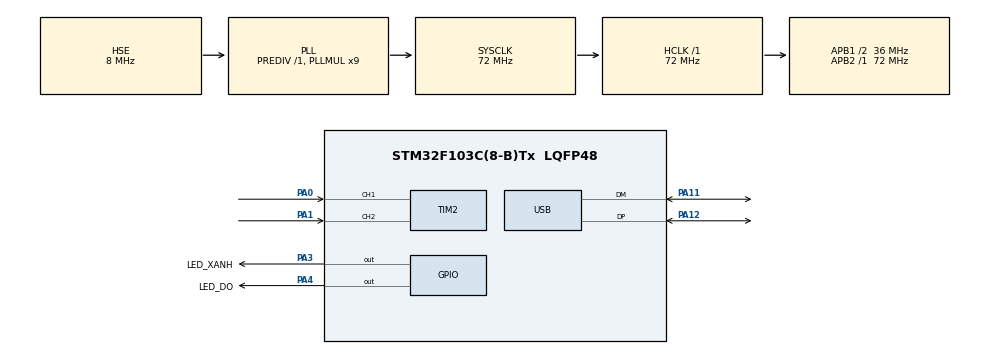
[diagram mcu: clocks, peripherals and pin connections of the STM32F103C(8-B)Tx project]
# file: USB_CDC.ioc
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Mcu.Family=STM32F1
Mcu.Name=STM32F103C(8-B)Tx
Mcu.Package=LQFP48
NVIC.PriorityGroup=NVIC_PRIORITYGROUP_4
NVIC.TIM3_IRQn=true\:0\:0\:false\:false\:true\:true\:true\:true
NVIC.USB_LP_CAN1_RX0_IRQn=true\:0\:0\:false\:false\:true\:false\:true\:true
PA0-WKUP.Signal=S_TIM2_CH1_ETR
PA1.Signal=S_TIM2_CH2
PA11.Mode=Device
PA11.Signal=USB_DM
PA12.Mode=Device
PA12.Signal=USB_DP
PA13.Mode=Serial_Wire
PA13.Signal=SYS_JTMS-SWDIO
PA14.Mode=Serial_Wire
PA14.Signal=SYS_JTCK-SWCLK
PA3.GPIO_Label=LED_XANH
PA3.GPIO_PuPd=GPIO_NOPULL
PA3.Signal=GPIO_Output
PA4.GPIO_Label=LED_DO
PA4.GPIO_PuPd=GPIO_NOPULL
PA4.Signal=GPIO_Output
PD0-OSC_IN.Mode=HSE-External-Oscillator
PD0-OSC_IN.Signal=RCC_OSC_IN
PD1-OSC_OUT.Mode=HSE-External-Oscillator
PD1-OSC_OUT.Signal=RCC_OSC_OUT
ProjectManager.HeapSize=0x200
ProjectManager.StackSize=0x400
ProjectManager.TargetToolchain=MDK-ARM V5
RCC.AHBFreq_Value=72000000
RCC.APB1CLKDivider=RCC_HCLK_DIV2
RCC.APB1Freq_Value=36000000
RCC.APB1TimFreq_Value=72000000
RCC.APB2Freq_Value=72000000
RCC.APB2TimFreq_Value=72000000
RCC.HCLKFreq_Value=72000000
RCC.PLLMUL=RCC_PLL_MUL9
RCC.PLLSourceVirtual=RCC_PLLSOURCE_HSE
RCC.SYSCLKFreq_VALUE=72000000
RCC.SYSCLKSource=RCC_SYSCLKSOURCE_PLLCLK
RCC.USBFreq_Value=48000000
RCC.USBPrescaler=RCC_USBCLKSOURCE_PLL_DIV1_5
SH.S_TIM2_CH1_ETR.0=TIM2_CH1,Encoder_Interface
SH.S_TIM2_CH2.0=TIM2_CH2,Encoder_Interface
TIM2.EncoderMode=TIM_ENCODERMODE_TI12
TIM3.Period=9999
TIM3.Prescaler=7199
USB_DEVICE.APP_RX_DATA_SIZE=128
USB_DEVICE.APP_TX_DATA_SIZE=128
USB_DEVICE.CLASS_NAME_FS=CDC
USB_DEVICE.VirtualMode=Cdc
USB_DEVICE.VirtualModeFS=Cdc_FS
VP_TIM3_VS_ClockSourceINT.Mode=Internal
VP_USB_DEVICE_VS_USB_DEVICE_CDC_FS.Mode=CDC_FS
board=custom

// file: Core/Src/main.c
/* USER CODE BEGIN Header */
/**
  ******************************************************************************
  * @file           : main.c
  * @brief          : Main program body
  ******************************************************************************
  * @attention
  *
  * Copyright (c) 2023 STMicroelectronics.
  * All rights reserved.
  *
  * This software is licensed under terms that can be found in the LICENSE file
  * in the root directory of this software component.
  * If no LICENSE file comes with this software, it is provided AS-IS.
  *
  ******************************************************************************
  */
/* USER CODE END Header */
#include "main.h"
#include "usb_device.h"

/* USER CODE BEGIN Includes */
#include "usbd_cdc_if.h"
#include "string.h"
#include "stdlib.h"
volatile short dem_xung = 0, pre_dem = 0;
uint16_t rate = 0;
uint8_t Rx_Buffer[128];
uint8_t Tx_Buffer[128];
char Tx_B[128];
/* USER CODE END Includes */

/* USER CODE BEGIN PTD */
typedef struct {
	int32_t position;
	int16_t speed_by_encoder;  // don vi: xung/(tgian ngat timer)
	int16_t pre_speed_by_encoder;
	int16_t rate;
	short pre_counter;
	int32_t velocity;    // vong/phut
	int32_t pre_velocity;

} instance_encoder;
instance_encoder instance_enc;
/* USER CODE END PTD */

TIM_HandleTypeDef htim2;
TIM_HandleTypeDef htim3;

void SystemClock_Config(void);
static void MX_GPIO_Init(void);
static void MX_TIM2_Init(void);
static void MX_TIM3_Init(void);

/* USER CODE BEGIN 0 */
void encoder()
	{
		instance_enc.rate = htim2.Instance->CNT - instance_enc.pre_speed_by_encoder;
	    instance_enc.pre_speed_by_encoder = htim2.Instance->CNT;
        //instance_enc.speed_by_encoder = htim2.Instance->CNT;
	    //instance_enc.position += instance_enc.rate;
	}

	void HAL_TIM_PeriodElapsedCallback(TIM_HandleTypeDef *htim)
{
	if(htim->Instance == TIM3)
	{
		encoder();
	}
}
/* USER CODE END 0 */

int main(void)
{

  /* MCU Configuration--------------------------------------------------------*/

  /* Reset of all peripherals, Initializes the Flash interface and the Systick. */
  HAL_Init();

  /* Configure the system clock */
  SystemClock_Config();

  /* Initialize all configured peripherals */
  MX_GPIO_Init();
  MX_USB_DEVICE_Init();
  MX_TIM2_Init();
  MX_TIM3_Init();
  /* USER CODE BEGIN 2 */
  HAL_TIM_Encoder_Start(&htim2, TIM_CHANNEL_ALL);
	HAL_TIM_Base_Start_IT(&htim3);
	//HAL_GPIO_WritePin(LED_DO_GPIO_Port, LED_DO_Pin,GPIO_PIN_SET);
	//HAL_GPIO_WritePin(LED_XANH_GPIO_Port, LED_XANH_Pin,GPIO_PIN_SET);

  /* USER CODE END 2 */

  /* Infinite loop */
  while (1)
  {

    /* USER CODE BEGIN 3 */
		/*HAL_Delay(500);
		dem_xung = __HAL_TIM_GET_COUNTER(&htim2);
		rate = dem_xung-pre_dem;
		pre_dem=dem_xung;*/
	  //CDC_Receive_FS(Rx_Buffer,sizeof(Rx_Buffer));
		memset(Tx_Buffer,0,sizeof(Tx_Buffer));
		HAL_Delay(100);
		sprintf(Tx_B,"%d",instance_enc.rate);
		memcpy(Tx_Buffer,Tx_B,(sizeof(Tx_B)));
		CDC_Transmit_FS(Tx_Buffer,sizeof(Tx_Buffer));
		if(Rx_Buffer[0] == '0')
		{
			HAL_GPIO_WritePin(LED_DO_GPIO_Port, LED_DO_Pin,GPIO_PIN_SET);
		  HAL_GPIO_WritePin(LED_XANH_GPIO_Port, LED_XANH_Pin,GPIO_PIN_RESET);
		}
		else if(Rx_Buffer[0] == '1')
		{
			HAL_GPIO_WritePin(LED_XANH_GPIO_Port, LED_XANH_Pin,GPIO_PIN_SET);
		  HAL_GPIO_WritePin(LED_DO_GPIO_Port, LED_DO_Pin,GPIO_PIN_RESET);
		}
  }
  /* USER CODE END 3 */
}

void SystemClock_Config(void)
{
  RCC_OscInitTypeDef RCC_OscInitStruct = {0};
  RCC_ClkInitTypeDef RCC_ClkInitStruct = {0};
  RCC_PeriphCLKInitTypeDef PeriphClkInit = {0};

  /** Initializes the RCC Oscillators according to the specified parameters
  * in the RCC_OscInitTypeDef structure.
  */
  RCC_OscInitStruct.OscillatorType = RCC_OSCILLATORTYPE_HSE;
  RCC_OscInitStruct.HSEState = RCC_HSE_ON;
  RCC_OscInitStruct.HSEPredivValue = RCC_HSE_PREDIV_DIV1;
  RCC_OscInitStruct.HSIState = RCC_HSI_ON;
  RCC_OscInitStruct.PLL.PLLState = RCC_PLL_ON;
  RCC_OscInitStruct.PLL.PLLSource = RCC_PLLSOURCE_HSE;
  RCC_OscInitStruct.PLL.PLLMUL = RCC_PLL_MUL9;
  if (HAL_RCC_OscConfig(&RCC_OscInitStruct) != HAL_OK)
  {
    Error_Handler();
  }

  /** Initializes the CPU, AHB and APB buses clocks
  */
  RCC_ClkInitStruct.ClockType = RCC_CLOCKTYPE_HCLK|RCC_CLOCKTYPE_SYSCLK
                              |RCC_CLOCKTYPE_PCLK1|RCC_CLOCKTYPE_PCLK2;
  RCC_ClkInitStruct.SYSCLKSource = RCC_SYSCLKSOURCE_PLLCLK;
  RCC_ClkInitStruct.AHBCLKDivider = RCC_SYSCLK_DIV1;
  RCC_ClkInitStruct.APB1CLKDivider = RCC_HCLK_DIV2;
  RCC_ClkInitStruct.APB2CLKDivider = RCC_HCLK_DIV1;

  if (HAL_RCC_ClockConfig(&RCC_ClkInitStruct, FLASH_LATENCY_2) != HAL_OK)
  {
    Error_Handler();
  }
  PeriphClkInit.PeriphClockSelection = RCC_PERIPHCLK_USB;
  PeriphClkInit.UsbClockSelection = RCC_USBCLKSOURCE_PLL_DIV1_5;
  if (HAL_RCCEx_PeriphCLKConfig(&PeriphClkInit) != HAL_OK)
  {
    Error_Handler();
  }
}

static void MX_TIM2_Init(void)
{

  TIM_Encoder_InitTypeDef sConfig = {0};
  TIM_MasterConfigTypeDef sMasterConfig = {0};

  htim2.Instance = TIM2;
  htim2.Init.Prescaler = 0;
  htim2.Init.CounterMode = TIM_COUNTERMODE_UP;
  htim2.Init.Period = 65535;
  htim2.Init.ClockDivision = TIM_CLOCKDIVISION_DIV1;
  htim2.Init.AutoReloadPreload = TIM_AUTORELOAD_PRELOAD_DISABLE;
  sConfig.EncoderMode = TIM_ENCODERMODE_TI12;
  sConfig.IC1Polarity = TIM_ICPOLARITY_RISING;
  sConfig.IC1Selection = TIM_ICSELECTION_DIRECTTI;
  sConfig.IC1Prescaler = TIM_ICPSC_DIV1;
  sConfig.IC1Filter = 0;
  sConfig.IC2Polarity = TIM_ICPOLARITY_RISING;
  sConfig.IC2Selection = TIM_ICSELECTION_DIRECTTI;
  sConfig.IC2Prescaler = TIM_ICPSC_DIV1;
  sConfig.IC2Filter = 0;
  if (HAL_TIM_Encoder_Init(&htim2, &sConfig) != HAL_OK)
  {
    Error_Handler();
  }
  sMasterConfig.MasterOutputTrigger = TIM_TRGO_RESET;
  sMasterConfig.MasterSlaveMode = TIM_MASTERSLAVEMODE_DISABLE;
  if (HAL_TIMEx_MasterConfigSynchronization(&htim2, &sMasterConfig) != HAL_OK)
  {
    Error_Handler();
  }

}

static void MX_TIM3_Init(void)
{

  TIM_ClockConfigTypeDef sClockSourceConfig = {0};
  TIM_MasterConfigTypeDef sMasterConfig = {0};

  htim3.Instance = TIM3;
  htim3.Init.Prescaler = 7199;
  htim3.Init.CounterMode = TIM_COUNTERMODE_UP;
  htim3.Init.Period = 9999;
  htim3.Init.ClockDivision = TIM_CLOCKDIVISION_DIV1;
  htim3.Init.AutoReloadPreload = TIM_AUTORELOAD_PRELOAD_DISABLE;
  if (HAL_TIM_Base_Init(&htim3) != HAL_OK)
  {
    Error_Handler();
  }
  sClockSourceConfig.ClockSource = TIM_CLOCKSOURCE_INTERNAL;
  if (HAL_TIM_ConfigClockSource(&htim3, &sClockSourceConfig) != HAL_OK)
  {
    Error_Handler();
  }
  sMasterConfig.MasterOutputTrigger = TIM_TRGO_RESET;
  sMasterConfig.MasterSlaveMode = TIM_MASTERSLAVEMODE_DISABLE;
  if (HAL_TIMEx_MasterConfigSynchronization(&htim3, &sMasterConfig) != HAL_OK)
  {
    Error_Handler();
  }

}

static void MX_GPIO_Init(void)
{
  GPIO_InitTypeDef GPIO_InitStruct = {0};

  /* GPIO Ports Clock Enable */
  __HAL_RCC_GPIOC_CLK_ENABLE();
  __HAL_RCC_GPIOD_CLK_ENABLE();
  __HAL_RCC_GPIOA_CLK_ENABLE();

  /*Configure GPIO pin Output Level */
  HAL_GPIO_WritePin(LED_GPIO_Port, LED_Pin, GPIO_PIN_RESET);

  /*Configure GPIO pin Output Level */
  HAL_GPIO_WritePin(GPIOA, LED_XANH_Pin|LED_DO_Pin, GPIO_PIN_RESET);

  /*Configure GPIO pin : LED_Pin */
  GPIO_InitStruct.Pin = LED_Pin;
  GPIO_InitStruct.Mode = GPIO_MODE_OUTPUT_PP;
  GPIO_InitStruct.Pull = GPIO_NOPULL;
  GPIO_InitStruct.Speed = GPIO_SPEED_FREQ_LOW;
  HAL_GPIO_Init(LED_GPIO_Port, &GPIO_InitStruct);

  /*Configure GPIO pins : LED_XANH_Pin LED_DO_Pin */
  GPIO_InitStruct.Pin = LED_XANH_Pin|LED_DO_Pin;
  GPIO_InitStruct.Mode = GPIO_MODE_OUTPUT_PP;
  GPIO_InitStruct.Pull = GPIO_NOPULL;
  GPIO_InitStruct.Speed = GPIO_SPEED_FREQ_LOW;
  HAL_GPIO_Init(GPIOA, &GPIO_InitStruct);

}

void Error_Handler(void)
{
  __disable_irq();
  while (1)
  {
  }
}
